# RK3399-AP register map
File version: 1
CPU: CA7 r0p1, little endian, MPU, FPU, I-cache, D-cache, VTOR, 4 interrupt priority bits, 0 interrupts
Registers are 32-bit, read-write, reset 0x0 unless marked. A register's access mark holds for its fields unless they carry their own. Offsets are from the block's base; [hi:lo] are bit positions; 'fields as' and 'values as' point back to an identical list.

## TSADC
Base 0xFF260000
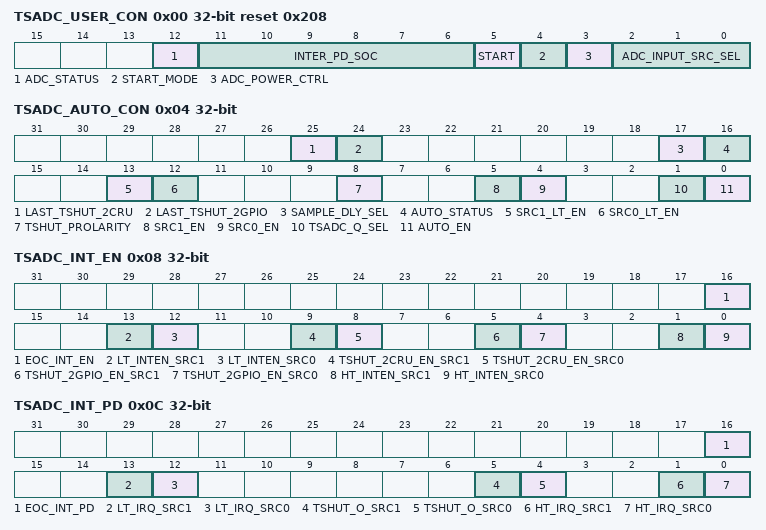
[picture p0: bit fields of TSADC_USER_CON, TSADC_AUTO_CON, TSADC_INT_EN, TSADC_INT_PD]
0x00 TSADC_USER_CON access per field reset 0x208 — The control register of A/D Converter.
  [12] ADC_STATUS ro — ADC status (EOC) 0: ADC stop 1: Conversion in progress
  [11:6] INTER_PD_SOC rw — interleave between power down and start of conversion
  [5] START rw — When software write 1 to this bit , start_of_conversion will be assert. This bit will be cleared after TSADC access finishing. When TSADC_USER_CON[4] = 1\'b1 take effect.
  [4] START_MODE rw — start mode. 0: tsadc controller will asert start_of_conversion after "inter_pd_soc" cycles. 1: the start_of_conversion will be controlled by TSADC_USER_CON[5].
  [3] ADC_POWER_CTRL rw — ADC power down control bit 0: ADC power down 1: ADC power up and reset
  [2:0] ADC_INPUT_SRC_SEL rw — ADC input source selection(CH_SEL[2:0]). 000 : Input source 0 (SARADC_AIN[0]) 001 : Input source 1 (SARADC_AIN[1]) Others : Reserved
0x04 TSADC_AUTO_CON access per field — TSADC auto mode control register
  [25] LAST_TSHUT_2CRU rw — last_tshut_2cru for cru first/second reset TSHUT status. This bit will set to 1 when tshut is valid, and only be cleared when application write 1 to it. This bit will not be cleared by system reset.
  [24] LAST_TSHUT_2GPIO rw — last_tshut_2gpio for hardware reset TSHUT status. This bit will set to 1 when tshut is valid, and only be cleared when application write 1 to it. This bit will not be cleared by system reset.
  [17] SAMPLE_DLY_SEL ro — 0: AUTO_PERIOD is used 1: AUTO_PERIOD_HT is used
  [16] AUTO_STATUS ro — 0: auto mode stop; 1: auto mode in progress.
  [13] SRC1_LT_EN rw — 0: do not care low temperature of source 0 1: enable the low temperature monitor of source 0
  [12] SRC0_LT_EN rw — 0: do not care low temperature of source 0 1: enable the low temperature monitor of source 0
  [8] TSHUT_PROLARITY rw — 0: low active 1: high active
  [5] SRC1_EN rw — 0: do not care the temperature of source 1 1: if the temperature of source 0 is too high , TSHUT will be valid
  [4] SRC0_EN rw — 0: do not care the temperature of source 0 1: if the temperature of source 0 is too high , TSHUT will be valid
  [1] TSADC_Q_SEL rw — temperature coefficient 1\'b0:use tsadc_q as output(positive temperature coefficient) 1\'b1:use(1024 - tsadc_q) as output (negative temperature coefficient) RK3399 is negative temprature coefficient, so please set this bit as 1\'b1
  [0] AUTO_EN rw — 0: TSADC controller works at user-define mode 1: TSADC controller works at auto mode
0x08 TSADC_INT_EN
  [16] EOC_INT_EN — eoc_Interrupt enable. eoc_interrupt enable in user defined mode 0: disable 1: enable
  [13] LT_INTEN_SRC1 — low temperature interrupt enable for src1 0: disable 1: enable
  [12] LT_INTEN_SRC0 — low temperature interrupt enable for src0 0: disable 1: enable
  [9] TSHUT_2CRU_EN_SRC1 — 0: TSHUT output to cru disabled. TSHUT output will always keep low . 1: TSHUT output works.
  [8] TSHUT_2CRU_EN_SRC0 — 0: TSHUT output to cru disabled. TSHUT output will always keep low . 1: TSHUT output works.
  [5] TSHUT_2GPIO_EN_SRC1 — 0: TSHUT output to gpio disabled. TSHUT output will always keep low . 1: TSHUT output works.
  [4] TSHUT_2GPIO_EN_SRC0 — 0: TSHUT output to gpio disabled. TSHUT output will always keep low . 1: TSHUT output works.
  [1] HT_INTEN_SRC1 — high temperature interrupt enable for src1 0: disable 1: enable
  [0] HT_INTEN_SRC0 — high temperature interrupt enable for src0 0: disable 1: enable
0x0C TSADC_INT_PD
  [16] EOC_INT_PD — Interrupt status. This bit will be set to 1 when end-of-conversion. Set 0 to clear the interrupt.
  [13] LT_IRQ_SRC1 — When TSADC output is lower than COMP_INT_LOW, this bit will be valid, which means temperature is low, and the application should in charge of this. write 1 to it , this bit will be cleared.
  [12] LT_IRQ_SRC0 — When TSADC output is lower than COMP_INT_LOW, this bit will be valid, which means temperature is low, and the application should in charge of this. write 1 to it , this bit will be cleared.
  [5] TSHUT_O_SRC1 — TSHUT output status When TSADC output is bigger than COMP_SHUT, this bit will be valid, which means temperature is VERY high, and the application should in charge of this. write 1 to it , this bit will be cleared.
  [4] TSHUT_O_SRC0 — TSHUT output status When TSADC output is bigger than COMP_SHUT, this bit will be valid, which means temperature is VERY high, and the application should in charge of this. write 1 to it , this bit will be cleared.
  [1] HT_IRQ_SRC1 — When TSADC output is bigger than COMP_INT, this bit will be valid, which means temperature is high, and the application should in charge of this. write 1 to it , this bit will be cleared.
  [0] HT_IRQ_SRC0 — When TSADC output is bigger than COMP_INT, this bit will be valid, which means temperature is high, and the application should in charge of this. write 1 to it , this bit will be cleared.
0x20 TSADC_DATA0 ro — This register contains the data after A/D Conversion.
  [11:0] ADC_DATA — A/D value of the channel 0 last conversion (DOUT[9:0]).
0x24 TSADC_DATA1 ro — This register contains the data after A/D Conversion.
  fields as TSADC_DATA0
0x30 TSADC_COMP0_INT — TSADC high temperature level for source 0
  [11:0] TSADC_COMP_SRC0 — TSADC high temperature level. TSADC output is bigger than tsadc_comp, means the temperature is high. TSADC_INT will be valid.
0x34 TSADC_COMP1_INT — TSADC high temperature level for source 1
  [11:0] TSADC_COMP_SRC1 — TSADC high temperature level. TSADC output is bigger than tsadc_comp, means the temperature is high. TSADC_INT will be valid.
0x40 TSADC_COMP0_SHUT — TSADC high temperature level for source 0
  [11:0] TSADC_COMP_SRC0 — TSADC high temperature level. TSADC output is bigger than tsadc_comp, means the temperature is too high. TSHUT will be valid.
0x44 TSADC_COMP1_SHUT — TSADC high temperature level for source 1
  [11:0] TSADC_COMP_SRC1 — TSADC high temperature level. TSADC output is bigger than tsadc_comp, means the temperature is too high. TSHUT will be valid.
0x60 TSADC_HIGHT_INT_DEBOUNCE reset 0x3 — high temperature debounce
  [7:0] DEBOUNCE — TSADC controller will only generate interrupt or TSHUT when temperature is higher than COMP_INT for "debounce" times.
0x64 TSADC_HIGHT_TSHUT_DEBOUNCE reset 0x3 — high temperature debounce
  [7:0] DEBOUNCE — TSADC controller will only generate interrupt or TSHUT when temperature is higher than COMP_SHUT for "debounce" times.
0x68 TSADC_AUTO_PERIOD reset 0x10000 — TSADC auto access period
  [31:0] AUTO_PERIOD — when auto mode is enabled, this register controls the interleave between every two accessing of TSADC.
0x6C TSADC_AUTO_PERIOD_HT reset 0x10000 — TSADC auto access period when temperature is high
  [31:0] AUTO_PERIOD — This register controls the interleave between every two accessing of TSADC after the temperature is higher than COMP_SHUT or COMP_INT
0x80 TSADC_COMP0_LOW_INT — TSADC low temperature level for source 0
  [11:0] TSADC_COMP_SRC0 — TSADC low temperature level. TSADC output is lower than tsadc_comp, means the temperature is low. TSADC_LOW_INT will be valid.
0x84 TSADC_COMP1_LOW_INT — TSADC low temperature level for source 1
  [11:0] TSADC_COMP_SRC1 — TSADC low temperature level. TSADC output is lower than tsadc_comp, means the temperature is low. TSADC_LOW_INT will be valid.
